# HSI_PORTS register map
Vendor: Texas Instruments
Peripheral module from a debugger description file (folder omap5430_ES2_PUBLIC).
Registers are 32-bit, access per field, reset 0x1 unless marked. A register's access mark holds for its fields unless they carry their own. Offsets are as the file gives them; lines under a group give offsets from that group; [hi:lo] are bit positions; {n}, {i} and the like mark numbered series; 'fields as' and 'values as' point back to an identical list; <NAME> marks a mode.

## HSI_PORTS
0x00 HST_ID_Pp_0 ro reset not defined — Legacy identification on port p
  [31:0] ID_VAL — Legacy ID
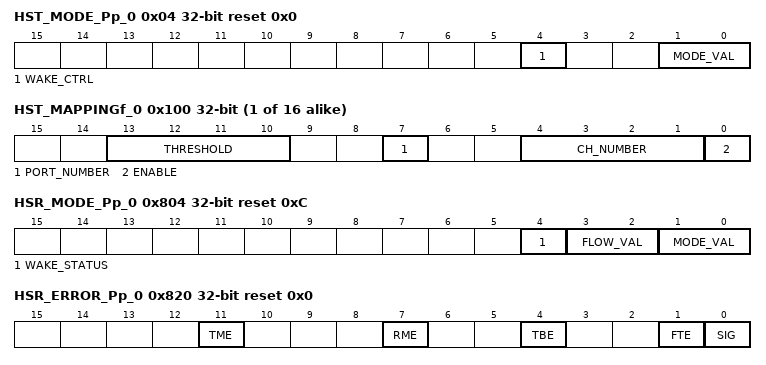
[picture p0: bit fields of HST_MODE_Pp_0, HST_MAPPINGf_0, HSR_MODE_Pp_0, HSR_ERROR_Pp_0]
0x04 HST_MODE_Pp_0 reset 0x0 — Defines operation mode and data flow on port p
  [4] WAKE_CTRL rw — Wake control
    0=Software_control; 1=Automatic_control
  [1:0] MODE_VAL rw — Mode
    0=Sleep; 1=Stream; 2=Frame
0x08 HST_FRAMESIZE_Pp_0 ro reset 0x1F — This register is provided for legacy and possible future extension of protocol. Returns 0x1f.
  [4:0] SIZE_VAL — In the current implementation it must be always written 31, meaning the frame payload size is 32 bits.
    31=Only_possible_value
0x0C HST_TXSTATE_Pp_0 ro reset 0x7 — Define the state of the transmitter on port p.
  [2:0] TXSTATEVAL — State of the transmitter
    0=Idle; 1=Wait; 2=Transmit; 3=Start; 4=Break; 7=Sleep_(disabled)
0x10 HST_BUFSTATE_Pp_0 ro reset 0x0 — Transmitter state for FIFO 0..7 Each bit gives the state of transmit FIFOs: 0x1: FIFO full 0x0: FIFO not full
  [7:0] BUFSTATE_VAL — Each bit gives the state of transmit buffer register: 0x0: Buffer is not full. 0x1: Buffer is full.
0x18 HST_DIVISOR_Pp_0 reset 0x0 — Transmission bit rate divisor for port p
  [7:0] TX_RATE_DIV_VAL rw — This bit field B has a range [0..255] and it programs a division factor [1..256], B + 1. Example: Writing 0 divides by 1, writing 1 divides by 2, writing 2 divides by 3, etc.
0x20 HST_BREAK_Pp_0 wo reset 0x0 — Transmit break strobe register on port p
  [0] BREAK_VAL — Send a break signal on the port
    0=No_break; 1=Transmit_break
0x24 HST_CHANNELS_Pp_0 — Number of active channels on port p (this determines the number of the used channel descriptor bits on the MIPI port as well) It can be 1, 2, 4, 8, or 16.
  [4:0] CHAN_NUM_VAL rw — Number of active channels up to 16
    1=One logical channel used, number of the channel descriptor bits is 0; 2=Two logical channels used, number of the channel descriptor bits is 1; 4=Four logical channels used, number of the channel descriptor bits is 2; 8=Eight logical channels used, number of the channel descriptor bits is 3; 16=Sixteen logical channels used, number of the channel descriptor bits is 4
0x28 HST_ARBMODE_Pp_0 reset 0x0 — Arbitration type for the transmit FIFOs on port p.
  [0] ARB_VAL rw — Mode
    0=Round_robin; 1=Priority
0x80 HST_BUFFER_Pp_CHN_i_0 wo reset 0x0 — Transmit register for FIFO 0..7 Important: Write access to the register with 0xC and 0xF byteen loads its value into the transmit FIFO. If using only 16- bit accesses, the lower 2 bytes must be written first (byteen 0x3). Between two consecutive 16-bit FIFO-related access there cannot be any other FIFO-related OCP access.
  [31:0] DATA — 32 bits of data
0xC0 HST_SWAPBUFFER_Pp_CHN_i_0 wo reset 0x0 — Transmit register with byte swapping for FIFO 0..7 Important: Write access to the register with 0x3 and 0xF byteen loads its value into the transmit FIFO. If using only 16-bit accesses, the upper 2 bytes must be written first (byteen 0xC). Between two consecutive 16-bit FIFO-related access there cannot be any other FIFO-related OCP access.
  [31:0] SWAPDATA — 32 bits of byte-swapped data
{0x100+4i} HST_MAPPINGf_{i} (i=0..15) — TX FIFO configuration register. One register per FIFO.
  [13:10] THRESHOLD rw — Number of empty TX FIFO locations that will activate interrupt or DMA requests.DMA requests (if enabled) or interrupt assertion (if enabled) is triggered if the number of free locations in FIFO is less than the THRESHOLD value. . … . 0x9 through 0xF: No request generated .
    0=Less_than_8_words_in_the_FIFO; 1=Less_than_1_words_in_the_FIFO; 2=Less_than_2_words_in_the_FIFO; 8=Less_than_8_words_in_the_FIFO
  [7] PORT_NUMBER rw — Associates the FIFO to a HSI port
    0=Port_1; 1=Port_2
  [4:1] CH_NUMBER rw — Associates the TX FIFO to a HSI logical channel number (0-15):… .
    0=Logical_channel_number_0; 1=Logical_channel_number_1; 15=Logical_channel_number_15
  [0] ENABLE rw — Enables the FIFO
    0=Disabled; 1=Enabled
0x800 HSR_ID_Pp_0 ro reset not defined — Legacy identification
  [31:0] ID_VAL — Legacy ID
0x804 HSR_MODE_Pp_0 reset 0xC (reset mask 0xFFFFFFEF) — Defines operation mode and data flow on port p
  [4] WAKE_STATUS ro — Level of WAKE line
  [3:2] FLOW_VAL rw — Flow
    0=Synchronized; 1=Pipelined; 2=Real-time; 3=Suspended
  [1:0] MODE_VAL rw — Mode
    0=Sleep_(disabled); 1=Stream; 2=Frame
0x808 HSR_FRAMESIZE_Pp_0 ro reset 0x1F — Legacy returns 0x1f
  [4:0] SIZE_VAL — 0x1F
0x80C HSR_RXSTATE_Pp_0 ro reset 0x7 — Receiver state on port p
  [2:0] RXSTATEVAL — RX state
    0=Idle; 1=Receiving; 2=Finished; 3=Error; 4=Halt; 5=Time-out; 7=Sleep_(disabled)
0x810 HSR_BUFSTATE_Pp_0 ro reset 0x0 — State of receiver buffer register for port p
  [7:0] BUFSTATE_VAL — Each bit gives the state of receiver buffer register: 0x0: Buffer is not full. 0x1: Buffer is full.
0x820 HSR_ERROR_Pp_0 ro reset 0x0 — Error detection state register for port p
  [11] TME — TX mapping error
  [7] RME — RX mapping error
  [4] TBE — Tailing bit error
  [1] FTE — Frame time-out error
  [0] SIG — Signal error (legacy)
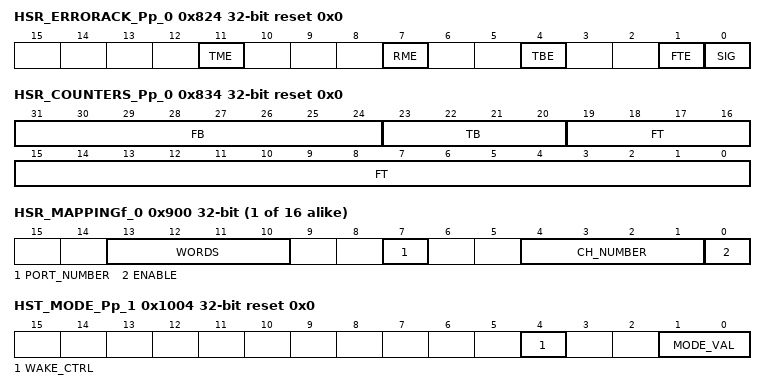
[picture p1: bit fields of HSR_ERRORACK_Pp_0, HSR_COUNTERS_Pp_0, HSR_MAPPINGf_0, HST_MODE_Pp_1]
0x824 HSR_ERRORACK_Pp_0 wo reset 0x0 — Error detection acknowledge register on port p: write 1 to clear.
  fields as HSR_ERROR_Pp_0
0x828 HSR_CHANNELS_Pp_0 — Number of active channels on port p (this determines the number of the used channel descriptor bits on the MIPI port as well) It can be 1, 2, 4, 8, or 16.
  [4:0] CHAN_NUM_VAL rw — Number of active channels
    values as HST_CHANNELS_Pp_0.CHAN_NUM_VAL
0x82C HSR_OVERRUN_Pp_0 ro reset 0x0 — Overrun detection state register for those receive FIFOs that are mapped to port p
  [15:0] OVERRUN_VAL — Bit n is set when overrun is detected on channel n
    1=Overrun_detected; 0=No_overrun
0x830 HSR_OVERRUNACK_Pp_0 reset 0x0 — Overrun acknowledge register for those receive FIFOs that are mapped to port p
  [15:0] OVERRUNACK_VAL wo — Bit n is set when overrun is acknowledged on channel n.
    0=No_action; 1=Overrun_acknowledge
0x834 HSR_COUNTERS_Pp_0 rw reset 0x0 — Counters setting register for port p
  [31:24] FB — Setting for Frame Burst Counter. Setting n as a value results in n + 1 counter value.
  [23:20] TB — Setting for Tailing Bit Counter. Setting n as a value results in n + 1 counter value.
  [19:0] FT — Setting for Frame Time-out counter. Set n as a value results in n+1 counter value.
0x880 HSR_BUFFER_Pp_CHN_i_0 ro reset not defined — Receive register for receive FIFO 0..7 Important: Read access to the register with 0xC and 0xF byteen removes the receive FIFO-related item. If using only 16-bit accesses, the lower 2 bytes must be read first (byteen 0x3). Between two consecutive 16-bit FIFO-related access there cannot be any other FIFO-related OCP access.
  [31:0] DATA — Received data
0x8C0 HSR_SWAPBUFFER_Pp_CHN_i_0 ro reset not defined — Byte swapped receive register for receive FIFO 0..7 Important: Read access to the register with 0x3 and 0xF byteen removes the receive FIFO-related item. If using only 16-bit accesses, the upper 2 bytes must be read first (byteen 0xC). Between two consecutive 16-bit FIFO-related access there cannot be any other FIFO- related OCP access.
  [31:0] SWAPDATA — Received data swapped
{0x900+4i} HSR_MAPPINGf_{i} (i=0..15) — RX FIFO Configuration register. One register per FIFO.
  [13:10] WORDS ro — Number of words available in the RX FIFO for reading
  [7] PORT_NUMBER rw — Associates the RX FIFO to a HSI port
    0=Port_1; 1=Port_2
  [4:1] CH_NUMBER rw — Associates RX FIFO to a HSI logical channel 0x0: Logical channel number 0 0x1: Logical channel number 1 … 0xF: Logical channel number 15
  [0] ENABLE rw — Enables or disables RX FIFO
    0=Disabled; 1=Enabled
0x94C HSR_DIVISOR_Pp_0 reset 0x0 — Receive bit rate divisor for port p. This must be set for correct protocol timing detection (tailing time-out, frame time-out).
  [7:0] RX_RATE_DIV_VAL rw — The functional clock source divided by this value is used as a clock base for the receive counters. Setting n as a value results in the n + 1 divisor value.
0x1000 HST_ID_Pp_1 ro reset not defined — Legacy identification on port p
  [31:0] ID_VAL — Legacy ID
0x1004 HST_MODE_Pp_1 reset 0x0 — Defines operation mode and data flow on port p
  fields as HST_MODE_Pp_0
0x1008 HST_FRAMESIZE_Pp_1 ro reset 0x1F — This register is provided for legacy and possible future extension of protocol. Returns 0x1f.
  fields as HST_FRAMESIZE_Pp_0
0x100C HST_TXSTATE_Pp_1 ro reset 0x7 — Define the state of the transmitter on port p.
  fields as HST_TXSTATE_Pp_0
0x1010 HST_BUFSTATE_Pp_1 ro reset 0x0 — Transmitter state for FIFO 0..7 Each bit gives the state of transmit FIFOs: 0x1: FIFO full 0x0: FIFO not full
  fields as HST_BUFSTATE_Pp_0
0x1018 HST_DIVISOR_Pp_1 reset 0x0 — Transmission bit rate divisor for port p
  fields as HST_DIVISOR_Pp_0
0x1020 HST_BREAK_Pp_1 wo reset 0x0 — Transmit break strobe register on port p
  fields as HST_BREAK_Pp_0
0x1024 HST_CHANNELS_Pp_1 — Number of active channels on port p (this determines the number of the used channel descriptor bits on the MIPI port as well) It can be 1, 2, 4, 8, or 16.
  fields as HST_CHANNELS_Pp_0
0x1028 HST_ARBMODE_Pp_1 reset 0x0 — Arbitration type for the transmit FIFOs on port p.
  [0] ARB_VAL rw — Mode
    0=Round_robin; 1=Priority
0x1080 HST_BUFFER_Pp_CHN_i_1 wo reset 0x0 — Transmit register for FIFO 0..7 Important: Write access to the register with 0xC and 0xF byteen loads its value into the transmit FIFO. If using only 16- bit accesses, the lower 2 bytes must be written first (byteen 0x3). Between two consecutive 16-bit FIFO-related access there cannot be any other FIFO-related OCP access.
  [31:0] DATA — 32 bits of data
0x10C0 HST_SWAPBUFFER_Pp_CHN_i_1 wo reset 0x0 — Transmit register with byte swapping for FIFO 0..7 Important: Write access to the register with 0x3 and 0xF byteen loads its value into the transmit FIFO. If using only 16-bit accesses, the upper 2 bytes must be written first (byteen 0xC). Between two consecutive 16-bit FIFO-related access there cannot be any other FIFO-related OCP access.
  [31:0] SWAPDATA — 32 bits of byte-swapped data
0x1800 HSR_ID_Pp_1 ro reset not defined — Legacy identification
  [31:0] ID_VAL — Legacy ID
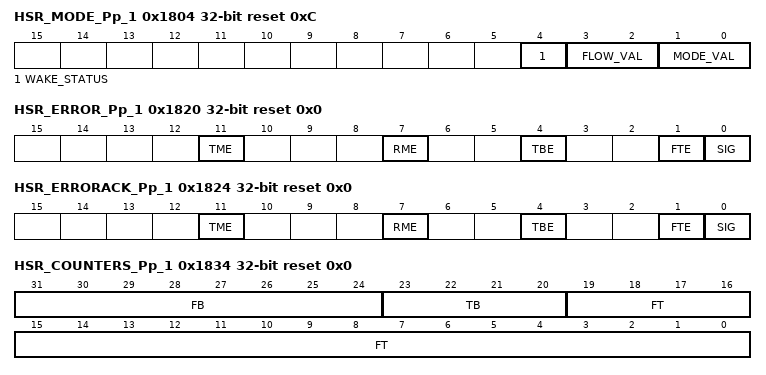
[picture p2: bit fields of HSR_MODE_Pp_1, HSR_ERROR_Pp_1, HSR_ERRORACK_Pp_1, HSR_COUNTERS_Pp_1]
0x1804 HSR_MODE_Pp_1 reset 0xC (reset mask 0xFFFFFFEF) — Defines operation mode and data flow on port p
  fields as HSR_MODE_Pp_0
0x1808 HSR_FRAMESIZE_Pp_1 ro reset 0x1F — Legacy returns 0x1f
  [4:0] SIZE_VAL — 0x1F
0x180C HSR_RXSTATE_Pp_1 ro reset 0x7 — Receiver state on port p
  fields as HSR_RXSTATE_Pp_0
0x1810 HSR_BUFSTATE_Pp_1 ro reset 0x0 — State of receiver buffer register for port p
  fields as HSR_BUFSTATE_Pp_0
0x1820 HSR_ERROR_Pp_1 ro reset 0x0 — Error detection state register for port p
  fields as HSR_ERROR_Pp_0
0x1824 HSR_ERRORACK_Pp_1 wo reset 0x0 — Error detection acknowledge register on port p: write 1 to clear.
  fields as HSR_ERROR_Pp_0
0x1828 HSR_CHANNELS_Pp_1 — Number of active channels on port p (this determines the number of the used channel descriptor bits on the MIPI port as well) It can be 1, 2, 4, 8, or 16.
  fields as HSR_CHANNELS_Pp_0
0x182C HSR_OVERRUN_Pp_1 ro reset 0x0 — Overrun detection state register for those receive FIFOs that are mapped to port p
  fields as HSR_OVERRUN_Pp_0
0x1830 HSR_OVERRUNACK_Pp_1 reset 0x0 — Overrun acknowledge register for those receive FIFOs that are mapped to port p
  fields as HSR_OVERRUNACK_Pp_0
0x1834 HSR_COUNTERS_Pp_1 rw reset 0x0 — Counters setting register for port p
  fields as HSR_COUNTERS_Pp_0
0x1880 HSR_BUFFER_Pp_CHN_i_1 ro reset not defined — Receive register for receive FIFO 0..7 Important: Read access to the register with 0xC and 0xF byteen removes the receive FIFO-related item. If using only 16-bit accesses, the lower 2 bytes must be read first (byteen 0x3). Between two consecutive 16-bit FIFO-related access there cannot be any other FIFO-related OCP access.
  [31:0] DATA — Received data
0x18C0 HSR_SWAPBUFFER_Pp_CHN_i_1 ro reset not defined — Byte swapped receive register for receive FIFO 0..7 Important: Read access to the register with 0x3 and 0xF byteen removes the receive FIFO-related item. If using only 16-bit accesses, the upper 2 bytes must be read first (byteen 0xC). Between two consecutive 16-bit FIFO-related access there cannot be any other FIFO- related OCP access.
  [31:0] SWAPDATA — Received data swapped
0x194C HSR_DIVISOR_Pp_1 reset 0x0 — Receive bit rate divisor for port p. This must be set for correct protocol timing detection (tailing time-out, frame time-out).
  fields as HSR_DIVISOR_Pp_0
